VERSION ""

NS_ :

BS_:
BU_: VCU VDM SME BATT STEERING_WHEEL TPERIPH_FL TPERIPH_FR TPERIPH_BL TPERIPH_BR IZZE1 CHARGER_BOARD SMPC

BA_DEF_ "BusType" STRING ;
BA_DEF_DEF_ "BusType" "";
BA_ "BusType" "CAN";

BO_ 128 SYNC: 0 VCU

BO_ 385 SMPC_UNKNOWN_1: 0 SMPC

BO_ 641 SMPC_UNKNOWN_2: 0 SMPC

BO_ 898 SMPC_UNKNOWN_3: 0 SMPC

BO_ 1793 SMPC_UNKNOWN_4: 0 SMPC

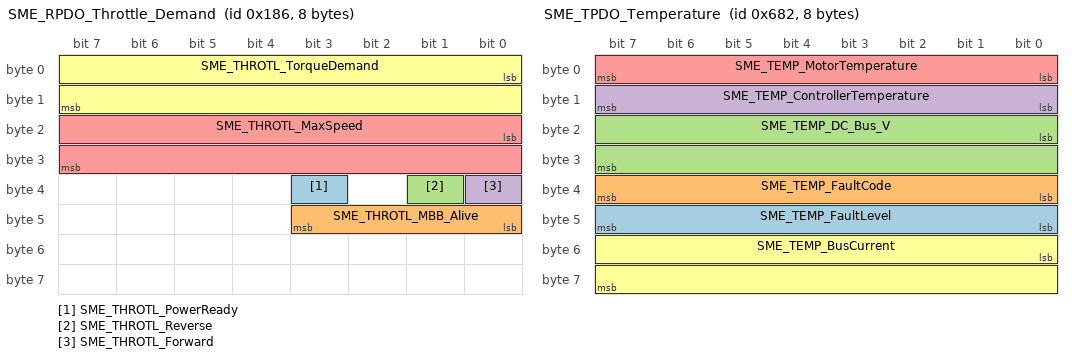
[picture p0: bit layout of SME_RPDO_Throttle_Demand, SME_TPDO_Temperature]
BO_ 390 SME_RPDO_Throttle_Demand: 8 VCU
   SG_ SME_THROTL_PowerReady : 35|1@1+ (1,0) [0|1] "" Vector__XXX
   SG_ SME_THROTL_MBB_Alive : 40|4@1+ (1,0) [0|15] "" Vector__XXX
   SG_ SME_THROTL_Reverse : 33|1@1+ (1,0) [0|1] "" Vector__XXX
   SG_ SME_THROTL_Forward : 32|1@1+ (1,0) [0|1] "" Vector__XXX
   SG_ SME_THROTL_MaxSpeed : 16|16@1- (1,0) [-32768|32767] "RPM" Vector__XXX
   SG_ SME_THROTL_TorqueDemand : 0|16@1- (1,0) [-32767|32767] "Q15" Vector__XXX

BO_ 646 SME_RPDO_Max_Currents: 8 VCU
   SG_ SME_CURRLIM_ChargeCurrentLim : 0|16@1+ (1,0) [0|65535] "A" Vector__XXX
   SG_ SME_CURRLIM_DischargeCurrentLim : 16|16@1+ (1,0) [0|65535] "A" Vector__XXX

BO_ 1154 SME_TPDO_Torque_speed: 8 SME
   SG_ SME_TRQSPD_SOC_Low_Traction : 32|1@1+ (1,0) [0|1] "" Vector__XXX
   SG_ SME_TRQSPD_SOC_Low_Hydraulic : 33|1@1+ (1,0) [0|1] "" Vector__XXX
   SG_ SME_TRQSPD_Reverse : 34|1@1+ (1,0) [0|1] "" Vector__XXX
   SG_ SME_TRQSPD_Forward : 35|1@1+ (1,0) [0|1] "" Vector__XXX
   SG_ SME_TRQSPD_Park_Brake : 36|1@1+ (1,0) [0|1] "" Vector__XXX
   SG_ SME_TRQSPD_Pedal_Brake : 37|1@1+ (1,0) [0|1] "" Vector__XXX
   SG_ SME_TRQSPD_Controller_Overtermp : 38|1@1+ (1,0) [0|1] "" Vector__XXX
   SG_ SME_TRQSPD_Key_Switch_Overvolt : 39|1@1+ (1,0) [0|1] "" Vector__XXX
   SG_ SME_TRQSPD_Key_Switch_Undervolt : 40|1@1+ (1,0) [0|1] "" Vector__XXX
   SG_ SME_TRQSPD_Running : 41|1@1+ (1,0) [0|1] "" Vector__XXX
   SG_ SME_TRQSPD_Traction : 42|1@1+ (1,0) [0|1] "" Vector__XXX
   SG_ SME_TRQSPD_Hydraulic : 43|1@1+ (1,0) [0|1] "" Vector__XXX
   SG_ SME_TRQSPD_Powering_Enabled : 44|1@1+ (1,0) [0|1] "" Vector__XXX
   SG_ SME_TRQSPD_Powering_Ready : 45|1@1+ (1,0) [0|1] "" Vector__XXX
   SG_ SME_TRQSPD_contactor_closed : 47|1@1+ (1,0) [0|1] "" Vector__XXX
   SG_ SME_TRQSPD_Precharging : 46|1@1+ (1,0) [0|1] "" Vector__XXX
   SG_ SME_TRQSPD_Speed : 0|16@1+ (1,0) [0|65535] "RPM" Vector__XXX
   SG_ SME_TRQSPD_MotorFlags : 48|16@1+ (1,0) [0|65535] "" Vector__XXX
   SG_ SME_TRQSPD_Torque : 16|16@1- (1,0) [-32767|32767] "Q15" Vector__XXX

BO_ 1666 SME_TPDO_Temperature: 8 SME
   SG_ SME_TEMP_FaultLevel : 40|8@1+ (1,0) [0|255] "" Vector__XXX
   SG_ SME_TEMP_FaultCode : 32|8@1+ (1,0) [0|255] "" Vector__XXX
   SG_ SME_TEMP_DC_Bus_V : 16|16@1+ (0.1,0) [0|6553.5] "V" Vector__XXX
   SG_ SME_TEMP_ControllerTemperature : 8|8@1+ (1,-40) [0|255] "C" Vector__XXX
   SG_ SME_TEMP_MotorTemperature : 0|8@1+ (1,-40) [0|255] "C" Vector__XXX
   SG_ SME_TEMP_BusCurrent : 48|16@1- (0.1,0) [-3276.8|3276.7] "A" Vector__XXX

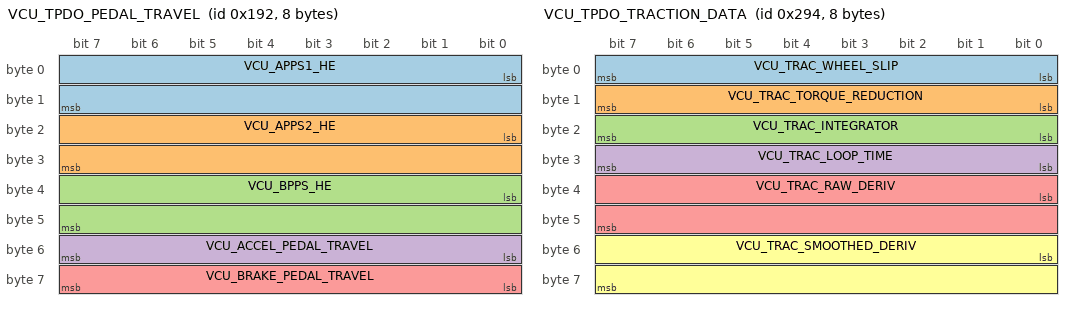
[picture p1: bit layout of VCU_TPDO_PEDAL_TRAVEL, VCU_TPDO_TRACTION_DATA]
BO_ 402 VCU_TPDO_PEDAL_TRAVEL: 8 VCU
   SG_ VCU_APPS1_HE : 0|16@1+ (1,0) [0|65535] "mV" Vector__XXX
   SG_ VCU_APPS2_HE : 16|16@1+ (1,0) [0|65535] "mV" Vector__XXX
   SG_ VCU_BPPS_HE : 32|16@1+ (1,0) [0|65535] "mV" Vector__XXX
   SG_ VCU_ACCEL_PEDAL_TRAVEL : 48|8@1+ (1,0) [0|100] "%" Vector__XXX
   SG_ VCU_BRAKE_PEDAL_TRAVEL : 56|8@1+ (1,0) [0|100] "%" Vector__XXX

BO_ 403 VCU_TPDO_STATUS: 8 VCU
   SG_ VCU_ETC_READY_TO_DRIVE : 0|1@1+ (1,0) [0|1] "" Vector__XXX
   SG_ VCU_ETC_MOTOR_ENABLED : 1|1@1+ (1,0) [0|1] "" Vector__XXX
   SG_ VCU_ETC_RTD_BUTTON_PRESSED : 2|1@1+ (1,0) [0|1] "" Vector__XXX
   SG_ VCU_ETC_BATT_PRECHARGE_DONE : 3|1@1+ (1,0) [0|1] "" Vector__XXX
   SG_ VCU_ETC_IMPLAUS_APPS_OUT_OF_RANGE : 4|1@1+ (1,0) [0|1] "" Vector__XXX
   SG_ VCU_ETC_IMPLAUS_BPPS_OUT_OF_RANGE : 5|1@1+ (1,0) [0|1] "" Vector__XXX
   SG_ VCU_ETC_IMPLAUS_APPS_DEVIATION : 6|1@1+ (1,0) [0|1] "" Vector__XXX
   SG_ VCU_ETC_IMPLAUS_BSE_OUT_OF_RANGE : 7|1@1+ (1,0) [0|1] "" Vector__XXX
   SG_ VCU_ETC_IMPLAUS_BRAKE_AND_ACCEL : 8|1@1+ (1,0) [0|1] "" Vector__XXX
   SG_ VCU_ETC_REVERSE : 9|1@1+ (1,0) [0|1] "" Vector__XXX
   SG_ VCU_ETC_BRAKELIGHT : 10|1@1+ (1,0) [0|1] "" Vector__XXX
   SG_ VCU_ETC_REGEN_ALLOWED : 11|1@1+ (1,0) [0|1] "" Vector__XXX
   SG_ VCU_ETC_SOLENOID_CLOSED : 12|1@1+ (1,0) [0|1] "" Vector__XXX
   SG_ VCU_BSPD_FAULT : 14|1@1+ (1,0) [0|1] "" Vector__XXX
   SG_ VCU_BSPD_SHUTDOWN_OUT : 15|1@1+ (1,0) [0|1] "" Vector__XXX
   SG_ VCU_BRAKE_PRESSSURE_FRONT : 16|16@1+ (1,0) [0|65535] "psi" Vector__XXX
   SG_ VCU_BRAKE_PRESSSURE_REAR : 32|16@1+ (1,0) [0|65535] "psi" Vector__XXX
   SG_ VCU_STEERING_ANGLE : 48|16@1- (0.01,0) [-327.68|327.67] "deg" Vector__XXX

  BO_ 660 VCU_TPDO_TRACTION_DATA: 8 VCU
    SG_ VCU_TRAC_WHEEL_SLIP : 0|8@1+ (0.01,0) [0|1] "" Vector__XXX
    SG_ VCU_TRAC_TORQUE_REDUCTION : 8|8@1+ (0.01,0) [0|1] "" Vector__XXX
    SG_ VCU_TRAC_INTEGRATOR : 16|8@1+ (0.01,0) [0|2.55] "" Vector__XXX
    SG_ VCU_TRAC_LOOP_TIME : 24|8@1+ (1,0) [10|255] "ms" Vector__XXX
    SG_ VCU_TRAC_RAW_DERIV : 32|16@1- (0.001,0) [-32.768|32.767] "" Vector__XXX
    SG_ VCU_TRAC_SMOOTHED_DERIV : 48|16@1- (0.001,0) [-32.768|32.767] "" Vector__XXX

BO_ 913 BATT_TPDO_STATUS: 8 BATT
   SG_ BATT_STATUS_BMS_FAULT : 0|1@1+ (1,0) [0|1] "" Vector__XXX
   SG_ BATT_STATUS_IMD_FAULT : 1|1@1+ (1,0) [0|1] "" Vector__XXX
   SG_ BATT_STATUS_SHUTDOWN_FINAL : 2|1@1+ (1,0) [0|1] "" Vector__XXX
   SG_ BATT_STATUS_SHUTDOWN_IN : 3|1@1+ (1,0) [0|1] "" Vector__XXX
   SG_ BATT_STATUS_SHUTDOWN_OUT : 4|1@1+ (1,0) [0|1] "" Vector__XXX
   SG_ BATT_STATUS_PRECHARGING : 5|1@1+ (1,0) [0|1] "" Vector__XXX
   SG_ BATT_STATUS_PRECHARGE_DONE : 6|1@1+ (1,0) [0|1] "" Vector__XXX
   SG_ BATT_STATUS_CHARGING : 7|1@1+ (1,0) [0|1] "" Vector__XXX
   SG_ BATT_STATUS_BALANCING : 8|1@1+ (1,0) [0|1] "" Vector__XXX
   SG_ BATT_STATUS_CELL_VOLTAGE_TOO_LOW : 9|1@1+ (1,0) [0|1] "" Vector__XXX
   SG_ BATT_STATUS_CELL_VOLTAGE_TOO_HIGH : 10|1@1+ (1,0) [0|1] "" Vector__XXX
   SG_ BATT_STATUS_PACK_TEMP_TOO_LOW : 11|1@1+ (1,0) [0|1] "" Vector__XXX
   SG_ BATT_STATUS_PACK_TEMP_TOO_HIGH : 12|1@1+ (1,0) [0|1] "" Vector__XXX
   SG_ BATT_STATUS_PACK_TEMP_TOO_HIGH_CRG : 13|1@1+ (1,0) [0|1] "" Vector__XXX
   SG_ BATT_STATUS_FAULT_MODULE_INDEX : 16|8@1+ (1,0) [0|4] "" Vector__XXX
   SG_ BATT_STATUS_FAULT_SENSOR_INDEX : 24|8@1+ (1,0) [0|11] "" Vector__XXX
   SG_ BATT_STATUS_FAULT_INDEX : 32|8@1+ (1,0) [0|60] "" Vector__XXX
   SG_ BATT_STATUS_GLV_VOLTAGE : 40|16@1+ (0.001,0) [0|65.635] "V" Vector__XXX
   SG_ BATT_STATUS_FAN_PWM_DUTY : 56|8@1+ (1,0) [0|100] "%" Vector__XXX

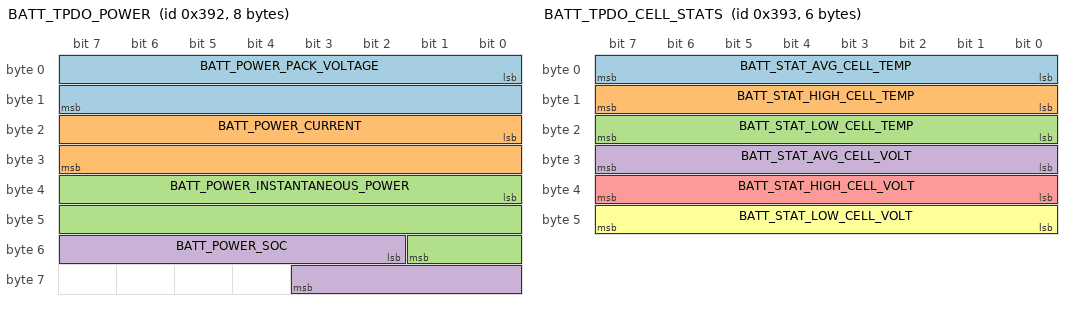
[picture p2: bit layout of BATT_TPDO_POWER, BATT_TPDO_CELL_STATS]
BO_ 914 BATT_TPDO_POWER: 8 BATT
   SG_ BATT_POWER_PACK_VOLTAGE : 0|16@1+ (0.01,0) [0|655.35] "V" Vector__XXX
   SG_ BATT_POWER_CURRENT : 16|16@1- (0.1,0) [-3276.8|3276.7] "A" Vector__XXX
   SG_ BATT_POWER_INSTANTANEOUS_POWER : 32|18@1- (1,0) [-131072|131071] "W" Vector__XXX
   SG_ BATT_POWER_SOC : 50|10@1+ (0.1,0) [0|100] "%" Vector__XXX

BO_ 915 BATT_TPDO_CELL_STATS: 6 BATT
   SG_ BATT_STAT_AVG_CELL_TEMP : 0|8@1+ (0.25,0) [0|64.0] "C" Vector__XXX
   SG_ BATT_STAT_HIGH_CELL_TEMP : 8|8@1+ (0.25,0) [0|64.0] "C" Vector__XXX
   SG_ BATT_STAT_LOW_CELL_TEMP : 16|8@1+ (0.25,0) [0|64.0] "C" Vector__XXX
   SG_ BATT_STAT_AVG_CELL_VOLT : 24|8@1+ (0.01,2) [2|4.55] "V" Vector__XXX
   SG_ BATT_STAT_HIGH_CELL_VOLT : 32|8@1+ (0.01,2) [2|4.55] "V" Vector__XXX
   SG_ BATT_STAT_LOW_CELL_VOLT : 40|8@1+ (0.01,2) [2|4.55] "V" Vector__XXX

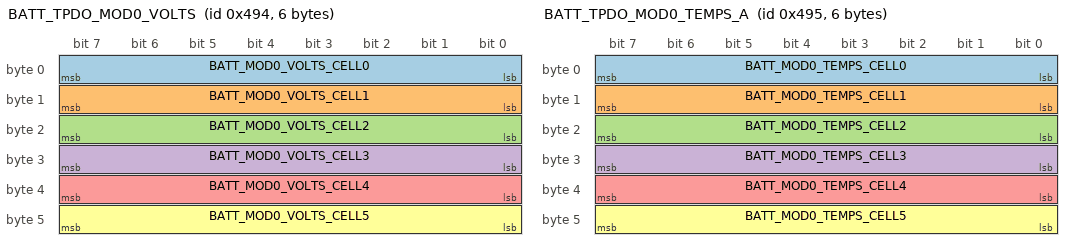
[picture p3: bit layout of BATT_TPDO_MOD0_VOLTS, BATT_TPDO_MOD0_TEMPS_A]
BO_ 1172 BATT_TPDO_MOD0_VOLTS: 6 BATT
   SG_ BATT_MOD0_VOLTS_CELL0 : 0|8@1+ (0.01,2) [2|4.55] "V" Vector__XXX
   SG_ BATT_MOD0_VOLTS_CELL1 : 8|8@1+ (0.01,2) [2|4.55] "V" Vector__XXX
   SG_ BATT_MOD0_VOLTS_CELL2 : 16|8@1+ (0.01,2) [2|4.55] "V" Vector__XXX
   SG_ BATT_MOD0_VOLTS_CELL3 : 24|8@1+ (0.01,2) [2|4.55] "V" Vector__XXX
   SG_ BATT_MOD0_VOLTS_CELL4 : 32|8@1+ (0.01,2) [2|4.55] "V" Vector__XXX
   SG_ BATT_MOD0_VOLTS_CELL5 : 40|8@1+ (0.01,2) [2|4.55] "V" Vector__XXX

BO_ 1173 BATT_TPDO_MOD0_TEMPS_A: 6 BATT
   SG_ BATT_MOD0_TEMPS_CELL0 : 0|8@1+ (0.25,0) [0|64.0] "C" Vector__XXX
   SG_ BATT_MOD0_TEMPS_CELL1 : 8|8@1+ (0.25,0) [0|64.0] "C" Vector__XXX
   SG_ BATT_MOD0_TEMPS_CELL2 : 16|8@1+ (0.25,0) [0|64.0] "C" Vector__XXX
   SG_ BATT_MOD0_TEMPS_CELL3 : 24|8@1+ (0.25,0) [0|64.0] "C" Vector__XXX
   SG_ BATT_MOD0_TEMPS_CELL4 : 32|8@1+ (0.25,0) [0|64.0] "C" Vector__XXX
   SG_ BATT_MOD0_TEMPS_CELL5 : 40|8@1+ (0.25,0) [0|64.0] "C" Vector__XXX

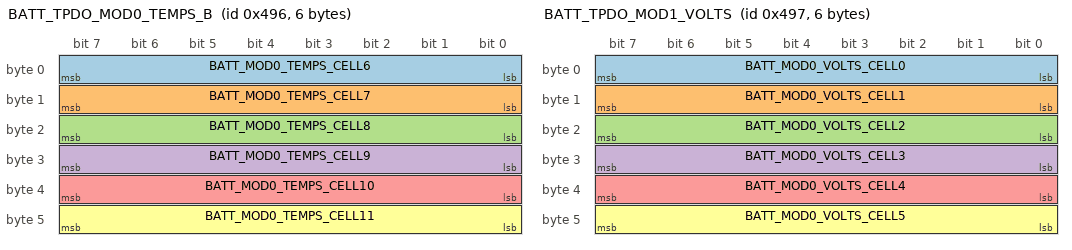
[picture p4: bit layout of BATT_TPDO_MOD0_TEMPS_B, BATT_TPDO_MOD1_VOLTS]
BO_ 1174 BATT_TPDO_MOD0_TEMPS_B: 6 BATT
   SG_ BATT_MOD0_TEMPS_CELL6 : 0|8@1+ (0.25,0) [0|64.0] "C" Vector__XXX
   SG_ BATT_MOD0_TEMPS_CELL7 : 8|8@1+ (0.25,0) [0|64.0] "C" Vector__XXX
   SG_ BATT_MOD0_TEMPS_CELL8 : 16|8@1+ (0.25,0) [0|64.0] "C" Vector__XXX
   SG_ BATT_MOD0_TEMPS_CELL9 : 24|8@1+ (0.25,0) [0|64.0] "C" Vector__XXX
   SG_ BATT_MOD0_TEMPS_CELL10 : 32|8@1+ (0.25,0) [0|64.0] "C" Vector__XXX
   SG_ BATT_MOD0_TEMPS_CELL11 : 40|8@1+ (0.25,0) [0|64.0] "C" Vector__XXX

BO_ 1175 BATT_TPDO_MOD1_VOLTS: 6 BATT
   SG_ BATT_MOD0_VOLTS_CELL0 : 0|8@1+ (0.01,2) [2|4.55] "V" Vector__XXX
   SG_ BATT_MOD0_VOLTS_CELL1 : 8|8@1+ (0.01,2) [2|4.55] "V" Vector__XXX
   SG_ BATT_MOD0_VOLTS_CELL2 : 16|8@1+ (0.01,2) [2|4.55] "V" Vector__XXX
   SG_ BATT_MOD0_VOLTS_CELL3 : 24|8@1+ (0.01,2) [2|4.55] "V" Vector__XXX
   SG_ BATT_MOD0_VOLTS_CELL4 : 32|8@1+ (0.01,2) [2|4.55] "V" Vector__XXX
   SG_ BATT_MOD0_VOLTS_CELL5 : 40|8@1+ (0.01,2) [2|4.55] "V" Vector__XXX

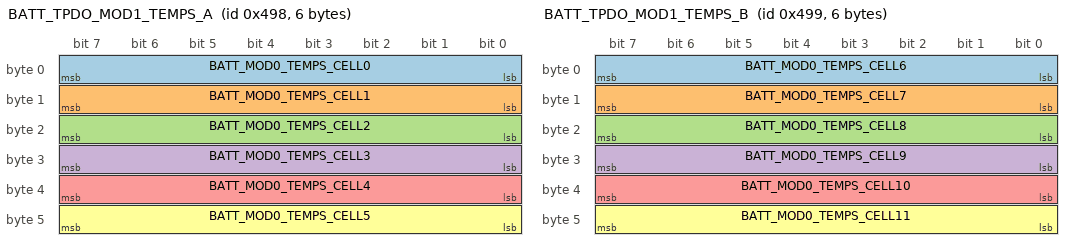
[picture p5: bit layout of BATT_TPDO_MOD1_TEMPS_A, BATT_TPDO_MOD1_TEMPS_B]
BO_ 1176 BATT_TPDO_MOD1_TEMPS_A: 6 BATT
   SG_ BATT_MOD0_TEMPS_CELL0 : 0|8@1+ (0.25,0) [0|64.0] "C" Vector__XXX
   SG_ BATT_MOD0_TEMPS_CELL1 : 8|8@1+ (0.25,0) [0|64.0] "C" Vector__XXX
   SG_ BATT_MOD0_TEMPS_CELL2 : 16|8@1+ (0.25,0) [0|64.0] "C" Vector__XXX
   SG_ BATT_MOD0_TEMPS_CELL3 : 24|8@1+ (0.25,0) [0|64.0] "C" Vector__XXX
   SG_ BATT_MOD0_TEMPS_CELL4 : 32|8@1+ (0.25,0) [0|64.0] "C" Vector__XXX
   SG_ BATT_MOD0_TEMPS_CELL5 : 40|8@1+ (0.25,0) [0|64.0] "C" Vector__XXX

BO_ 1177 BATT_TPDO_MOD1_TEMPS_B: 6 BATT
   SG_ BATT_MOD0_TEMPS_CELL6 : 0|8@1+ (0.25,0) [0|64.0] "C" Vector__XXX
   SG_ BATT_MOD0_TEMPS_CELL7 : 8|8@1+ (0.25,0) [0|64.0] "C" Vector__XXX
   SG_ BATT_MOD0_TEMPS_CELL8 : 16|8@1+ (0.25,0) [0|64.0] "C" Vector__XXX
   SG_ BATT_MOD0_TEMPS_CELL9 : 24|8@1+ (0.25,0) [0|64.0] "C" Vector__XXX
   SG_ BATT_MOD0_TEMPS_CELL10 : 32|8@1+ (0.25,0) [0|64.0] "C" Vector__XXX
   SG_ BATT_MOD0_TEMPS_CELL11 : 40|8@1+ (0.25,0) [0|64.0] "C" Vector__XXX

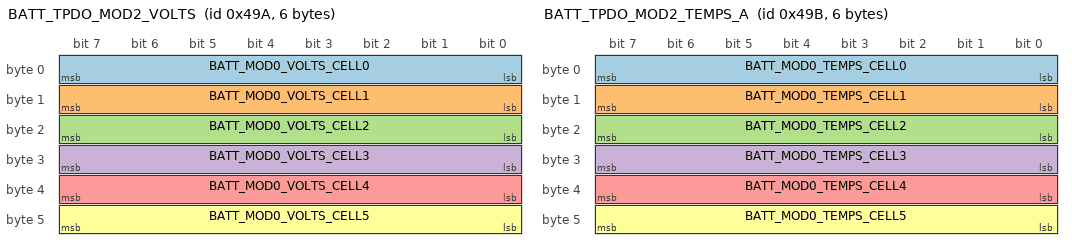
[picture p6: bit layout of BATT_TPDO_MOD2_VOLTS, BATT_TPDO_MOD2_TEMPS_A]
BO_ 1178 BATT_TPDO_MOD2_VOLTS: 6 BATT
   SG_ BATT_MOD0_VOLTS_CELL0 : 0|8@1+ (0.01,2) [2|4.55] "V" Vector__XXX
   SG_ BATT_MOD0_VOLTS_CELL1 : 8|8@1+ (0.01,2) [2|4.55] "V" Vector__XXX
   SG_ BATT_MOD0_VOLTS_CELL2 : 16|8@1+ (0.01,2) [2|4.55] "V" Vector__XXX
   SG_ BATT_MOD0_VOLTS_CELL3 : 24|8@1+ (0.01,2) [2|4.55] "V" Vector__XXX
   SG_ BATT_MOD0_VOLTS_CELL4 : 32|8@1+ (0.01,2) [2|4.55] "V" Vector__XXX
   SG_ BATT_MOD0_VOLTS_CELL5 : 40|8@1+ (0.01,2) [2|4.55] "V" Vector__XXX

BO_ 1179 BATT_TPDO_MOD2_TEMPS_A: 6 BATT
   SG_ BATT_MOD0_TEMPS_CELL0 : 0|8@1+ (0.25,0) [0|64.0] "C" Vector__XXX
   SG_ BATT_MOD0_TEMPS_CELL1 : 8|8@1+ (0.25,0) [0|64.0] "C" Vector__XXX
   SG_ BATT_MOD0_TEMPS_CELL2 : 16|8@1+ (0.25,0) [0|64.0] "C" Vector__XXX
   SG_ BATT_MOD0_TEMPS_CELL3 : 24|8@1+ (0.25,0) [0|64.0] "C" Vector__XXX
   SG_ BATT_MOD0_TEMPS_CELL4 : 32|8@1+ (0.25,0) [0|64.0] "C" Vector__XXX
   SG_ BATT_MOD0_TEMPS_CELL5 : 40|8@1+ (0.25,0) [0|64.0] "C" Vector__XXX

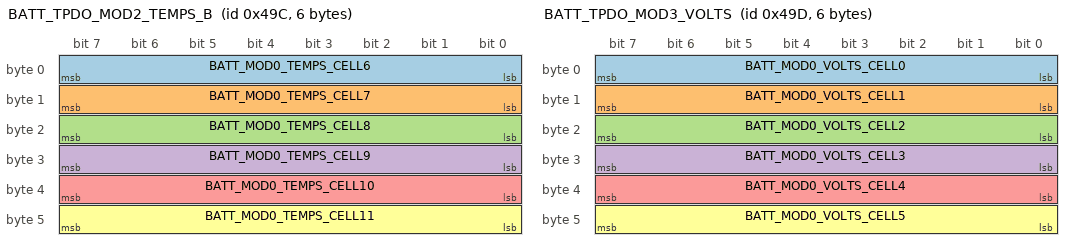
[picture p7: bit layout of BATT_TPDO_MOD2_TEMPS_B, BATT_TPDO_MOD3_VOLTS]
BO_ 1180 BATT_TPDO_MOD2_TEMPS_B: 6 BATT
   SG_ BATT_MOD0_TEMPS_CELL6 : 0|8@1+ (0.25,0) [0|64.0] "C" Vector__XXX
   SG_ BATT_MOD0_TEMPS_CELL7 : 8|8@1+ (0.25,0) [0|64.0] "C" Vector__XXX
   SG_ BATT_MOD0_TEMPS_CELL8 : 16|8@1+ (0.25,0) [0|64.0] "C" Vector__XXX
   SG_ BATT_MOD0_TEMPS_CELL9 : 24|8@1+ (0.25,0) [0|64.0] "C" Vector__XXX
   SG_ BATT_MOD0_TEMPS_CELL10 : 32|8@1+ (0.25,0) [0|64.0] "C" Vector__XXX
   SG_ BATT_MOD0_TEMPS_CELL11 : 40|8@1+ (0.25,0) [0|64.0] "C" Vector__XXX

BO_ 1181 BATT_TPDO_MOD3_VOLTS: 6 BATT
   SG_ BATT_MOD0_VOLTS_CELL0 : 0|8@1+ (0.01,2) [2|4.55] "V" Vector__XXX
   SG_ BATT_MOD0_VOLTS_CELL1 : 8|8@1+ (0.01,2) [2|4.55] "V" Vector__XXX
   SG_ BATT_MOD0_VOLTS_CELL2 : 16|8@1+ (0.01,2) [2|4.55] "V" Vector__XXX
   SG_ BATT_MOD0_VOLTS_CELL3 : 24|8@1+ (0.01,2) [2|4.55] "V" Vector__XXX
   SG_ BATT_MOD0_VOLTS_CELL4 : 32|8@1+ (0.01,2) [2|4.55] "V" Vector__XXX
   SG_ BATT_MOD0_VOLTS_CELL5 : 40|8@1+ (0.01,2) [2|4.55] "V" Vector__XXX

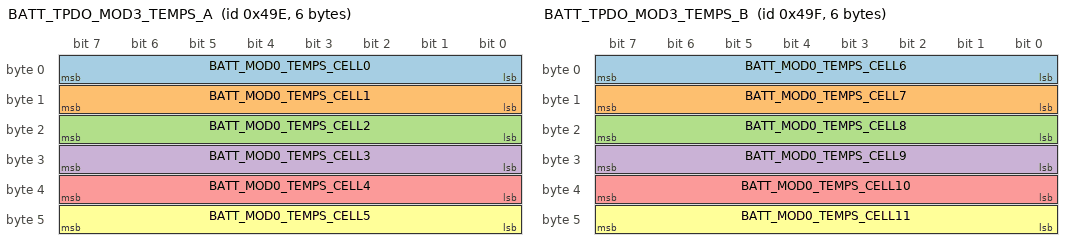
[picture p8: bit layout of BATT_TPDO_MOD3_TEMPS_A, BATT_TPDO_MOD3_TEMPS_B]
BO_ 1182 BATT_TPDO_MOD3_TEMPS_A: 6 BATT
   SG_ BATT_MOD0_TEMPS_CELL0 : 0|8@1+ (0.25,0) [0|64.0] "C" Vector__XXX
   SG_ BATT_MOD0_TEMPS_CELL1 : 8|8@1+ (0.25,0) [0|64.0] "C" Vector__XXX
   SG_ BATT_MOD0_TEMPS_CELL2 : 16|8@1+ (0.25,0) [0|64.0] "C" Vector__XXX
   SG_ BATT_MOD0_TEMPS_CELL3 : 24|8@1+ (0.25,0) [0|64.0] "C" Vector__XXX
   SG_ BATT_MOD0_TEMPS_CELL4 : 32|8@1+ (0.25,0) [0|64.0] "C" Vector__XXX
   SG_ BATT_MOD0_TEMPS_CELL5 : 40|8@1+ (0.25,0) [0|64.0] "C" Vector__XXX

BO_ 1183 BATT_TPDO_MOD3_TEMPS_B: 6 BATT
   SG_ BATT_MOD0_TEMPS_CELL6 : 0|8@1+ (0.25,0) [0|64.0] "C" Vector__XXX
   SG_ BATT_MOD0_TEMPS_CELL7 : 8|8@1+ (0.25,0) [0|64.0] "C" Vector__XXX
   SG_ BATT_MOD0_TEMPS_CELL8 : 16|8@1+ (0.25,0) [0|64.0] "C" Vector__XXX
   SG_ BATT_MOD0_TEMPS_CELL9 : 24|8@1+ (0.25,0) [0|64.0] "C" Vector__XXX
   SG_ BATT_MOD0_TEMPS_CELL10 : 32|8@1+ (0.25,0) [0|64.0] "C" Vector__XXX
   SG_ BATT_MOD0_TEMPS_CELL11 : 40|8@1+ (0.25,0) [0|64.0] "C" Vector__XXX

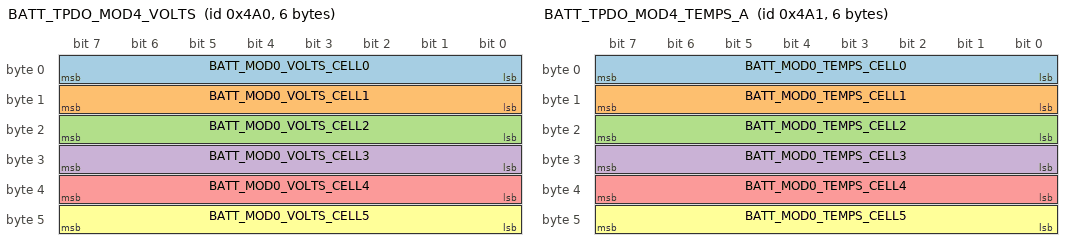
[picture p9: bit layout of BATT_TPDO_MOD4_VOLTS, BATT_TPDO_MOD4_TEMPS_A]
BO_ 1184 BATT_TPDO_MOD4_VOLTS: 6 BATT
   SG_ BATT_MOD0_VOLTS_CELL0 : 0|8@1+ (0.01,2) [2|4.55] "V" Vector__XXX
   SG_ BATT_MOD0_VOLTS_CELL1 : 8|8@1+ (0.01,2) [2|4.55] "V" Vector__XXX
   SG_ BATT_MOD0_VOLTS_CELL2 : 16|8@1+ (0.01,2) [2|4.55] "V" Vector__XXX
   SG_ BATT_MOD0_VOLTS_CELL3 : 24|8@1+ (0.01,2) [2|4.55] "V" Vector__XXX
   SG_ BATT_MOD0_VOLTS_CELL4 : 32|8@1+ (0.01,2) [2|4.55] "V" Vector__XXX
   SG_ BATT_MOD0_VOLTS_CELL5 : 40|8@1+ (0.01,2) [2|4.55] "V" Vector__XXX

BO_ 1185 BATT_TPDO_MOD4_TEMPS_A: 6 BATT
   SG_ BATT_MOD0_TEMPS_CELL0 : 0|8@1+ (0.25,0) [0|64.0] "C" Vector__XXX
   SG_ BATT_MOD0_TEMPS_CELL1 : 8|8@1+ (0.25,0) [0|64.0] "C" Vector__XXX
   SG_ BATT_MOD0_TEMPS_CELL2 : 16|8@1+ (0.25,0) [0|64.0] "C" Vector__XXX
   SG_ BATT_MOD0_TEMPS_CELL3 : 24|8@1+ (0.25,0) [0|64.0] "C" Vector__XXX
   SG_ BATT_MOD0_TEMPS_CELL4 : 32|8@1+ (0.25,0) [0|64.0] "C" Vector__XXX
   SG_ BATT_MOD0_TEMPS_CELL5 : 40|8@1+ (0.25,0) [0|64.0] "C" Vector__XXX

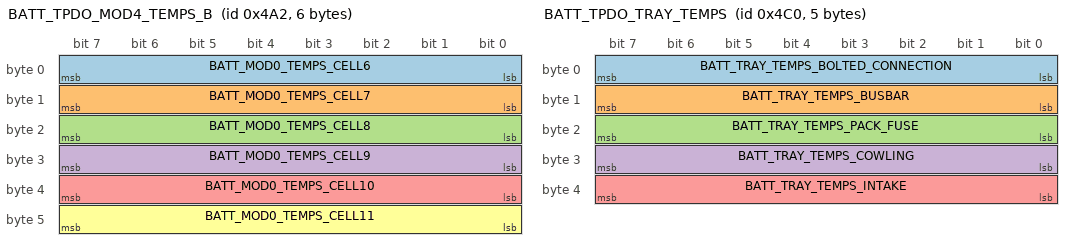
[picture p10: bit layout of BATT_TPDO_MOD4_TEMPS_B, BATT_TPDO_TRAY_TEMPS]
BO_ 1186 BATT_TPDO_MOD4_TEMPS_B: 6 BATT
   SG_ BATT_MOD0_TEMPS_CELL6 : 0|8@1+ (0.25,0) [0|64.0] "C" Vector__XXX
   SG_ BATT_MOD0_TEMPS_CELL7 : 8|8@1+ (0.25,0) [0|64.0] "C" Vector__XXX
   SG_ BATT_MOD0_TEMPS_CELL8 : 16|8@1+ (0.25,0) [0|64.0] "C" Vector__XXX
   SG_ BATT_MOD0_TEMPS_CELL9 : 24|8@1+ (0.25,0) [0|64.0] "C" Vector__XXX
   SG_ BATT_MOD0_TEMPS_CELL10 : 32|8@1+ (0.25,0) [0|64.0] "C" Vector__XXX
   SG_ BATT_MOD0_TEMPS_CELL11 : 40|8@1+ (0.25,0) [0|64.0] "C" Vector__XXX

BO_ 1216 BATT_TPDO_TRAY_TEMPS: 5 BATT
   SG_ BATT_TRAY_TEMPS_BOLTED_CONNECTION : 0|8@1+ (0.5,0) [0|127.5] "" Vector__XXX
   SG_ BATT_TRAY_TEMPS_BUSBAR : 8|8@1+ (0.5,0) [0|127.5] "" Vector__XXX
   SG_ BATT_TRAY_TEMPS_PACK_FUSE : 16|8@1+ (0.5,0) [0|127.5] "" Vector__XXX
   SG_ BATT_TRAY_TEMPS_COWLING : 24|8@1+ (0.5,0) [0|127.5] "" Vector__XXX
   SG_ BATT_TRAY_TEMPS_INTAKE : 32|8@1+ (0.5,0) [0|127.5] "" Vector__XXX

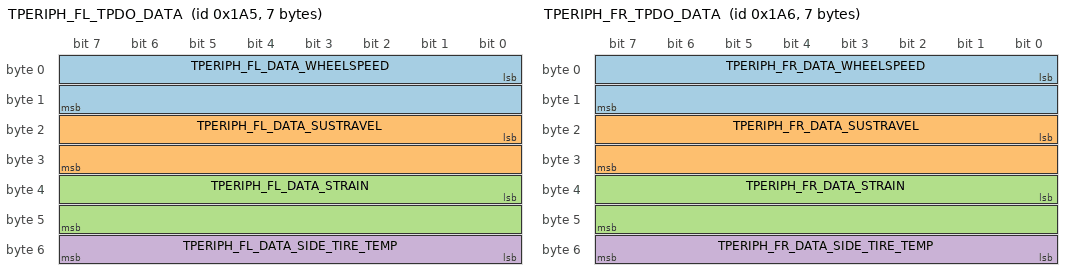
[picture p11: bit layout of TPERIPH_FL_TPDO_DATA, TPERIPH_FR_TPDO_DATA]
BO_ 421 TPERIPH_FL_TPDO_DATA: 7 TPERIPH_FL
   SG_ TPERIPH_FL_DATA_WHEELSPEED : 0|16@1- (0.1,0) [-3276.8|3276.7] "rpm" Vector__XXX
   SG_ TPERIPH_FL_DATA_SUSTRAVEL : 16|16@1+ (0.01,0) [0|655.35] "mm" Vector__XXX
   SG_ TPERIPH_FL_DATA_STRAIN : 32|16@1- (1e-07,0) [-0.032768|0.032767] "%" Vector__XXX
   SG_ TPERIPH_FL_DATA_SIDE_TIRE_TEMP : 48|8@1+ (1,0) [0|255] "C" Vector__XXX

BO_ 422 TPERIPH_FR_TPDO_DATA: 7 TPERIPH_FR
   SG_ TPERIPH_FR_DATA_WHEELSPEED : 0|16@1- (0.1,0) [-3276.8|3276.7] "rpm" Vector__XXX
   SG_ TPERIPH_FR_DATA_SUSTRAVEL : 16|16@1+ (0.01,0) [0|655.35] "mm" Vector__XXX
   SG_ TPERIPH_FR_DATA_STRAIN : 32|16@1- (1e-07,0) [-0.032768|0.032767] "%" Vector__XXX
   SG_ TPERIPH_FR_DATA_SIDE_TIRE_TEMP : 48|8@1+ (1,0) [0|255] "C" Vector__XXX

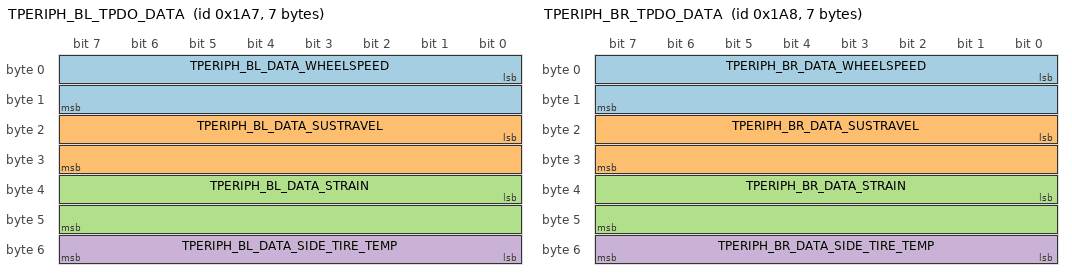
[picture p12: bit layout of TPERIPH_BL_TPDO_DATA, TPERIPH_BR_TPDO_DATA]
BO_ 423 TPERIPH_BL_TPDO_DATA: 7 TPERIPH_BL
   SG_ TPERIPH_BL_DATA_WHEELSPEED : 0|16@1- (0.1,0) [-3276.8|3276.7] "rpm" Vector__XXX
   SG_ TPERIPH_BL_DATA_SUSTRAVEL : 16|16@1+ (0.01,0) [0|655.35] "mm" Vector__XXX
   SG_ TPERIPH_BL_DATA_STRAIN : 32|16@1- (1e-07,0) [-0.032768|0.032767] "%" Vector__XXX
   SG_ TPERIPH_BL_DATA_SIDE_TIRE_TEMP : 48|8@1+ (1,0) [0|255] "C" Vector__XXX

BO_ 424 TPERIPH_BR_TPDO_DATA: 7 TPERIPH_BR
   SG_ TPERIPH_BR_DATA_WHEELSPEED : 0|16@1- (0.1,0) [-3276.8|3276.7] "rpm" Vector__XXX
   SG_ TPERIPH_BR_DATA_SUSTRAVEL : 16|16@1+ (0.01,0) [0|655.35] "mm" Vector__XXX
   SG_ TPERIPH_BR_DATA_STRAIN : 32|16@1- (1e-07,0) [-0.032768|0.032767] "%" Vector__XXX
   SG_ TPERIPH_BR_DATA_SIDE_TIRE_TEMP : 48|8@1+ (1,0) [0|255] "C" Vector__XXX

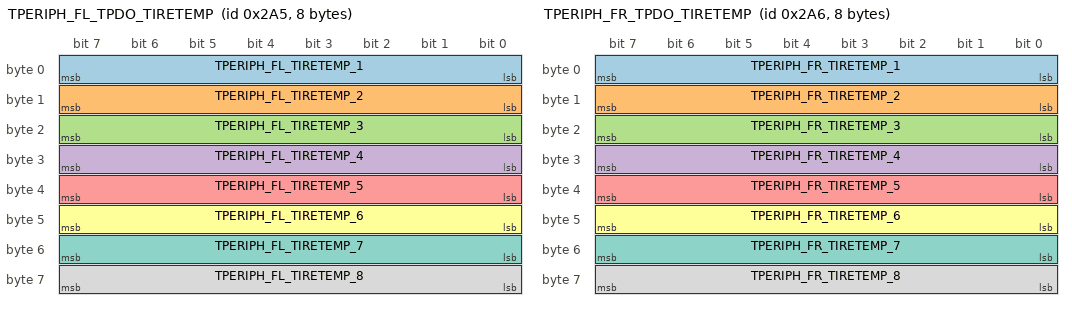
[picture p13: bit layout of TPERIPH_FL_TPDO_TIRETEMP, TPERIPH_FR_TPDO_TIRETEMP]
BO_ 677 TPERIPH_FL_TPDO_TIRETEMP: 8 TPERIPH_FL
   SG_ TPERIPH_FL_TIRETEMP_1 : 0|8@1+ (1,0) [0|255] "C" Vector__XXX
   SG_ TPERIPH_FL_TIRETEMP_2 : 8|8@1+ (1,0) [0|255] "C" Vector__XXX
   SG_ TPERIPH_FL_TIRETEMP_3 : 16|8@1+ (1,0) [0|255] "C" Vector__XXX
   SG_ TPERIPH_FL_TIRETEMP_4 : 24|8@1+ (1,0) [0|255] "C" Vector__XXX
   SG_ TPERIPH_FL_TIRETEMP_5 : 32|8@1+ (1,0) [0|255] "C" Vector__XXX
   SG_ TPERIPH_FL_TIRETEMP_6 : 40|8@1+ (1,0) [0|255] "C" Vector__XXX
   SG_ TPERIPH_FL_TIRETEMP_7 : 48|8@1+ (1,0) [0|255] "C" Vector__XXX
   SG_ TPERIPH_FL_TIRETEMP_8 : 56|8@1+ (1,0) [0|255] "C" Vector__XXX

BO_ 678 TPERIPH_FR_TPDO_TIRETEMP: 8 TPERIPH_FR
   SG_ TPERIPH_FR_TIRETEMP_1 : 0|8@1+ (1,0) [0|255] "C" Vector__XXX
   SG_ TPERIPH_FR_TIRETEMP_2 : 8|8@1+ (1,0) [0|255] "C" Vector__XXX
   SG_ TPERIPH_FR_TIRETEMP_3 : 16|8@1+ (1,0) [0|255] "C" Vector__XXX
   SG_ TPERIPH_FR_TIRETEMP_4 : 24|8@1+ (1,0) [0|255] "C" Vector__XXX
   SG_ TPERIPH_FR_TIRETEMP_5 : 32|8@1+ (1,0) [0|255] "C" Vector__XXX
   SG_ TPERIPH_FR_TIRETEMP_6 : 40|8@1+ (1,0) [0|255] "C" Vector__XXX
   SG_ TPERIPH_FR_TIRETEMP_7 : 48|8@1+ (1,0) [0|255] "C" Vector__XXX
   SG_ TPERIPH_FR_TIRETEMP_8 : 56|8@1+ (1,0) [0|255] "C" Vector__XXX

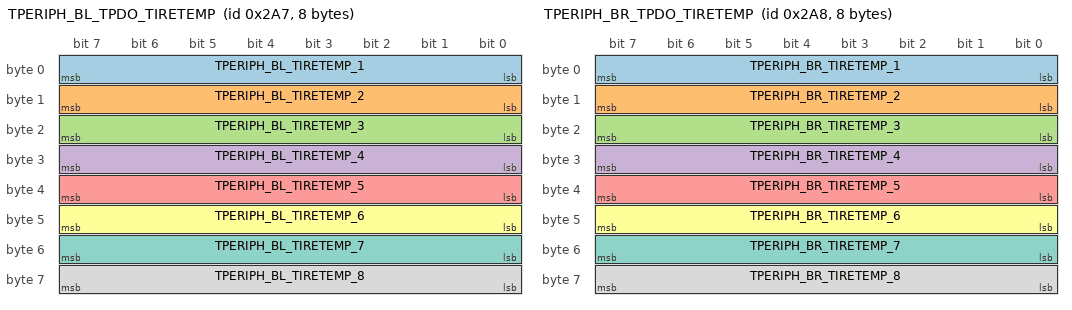
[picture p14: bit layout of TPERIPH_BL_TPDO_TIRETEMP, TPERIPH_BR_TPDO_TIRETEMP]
BO_ 679 TPERIPH_BL_TPDO_TIRETEMP: 8 TPERIPH_BL
   SG_ TPERIPH_BL_TIRETEMP_1 : 0|8@1+ (1,0) [0|255] "C" Vector__XXX
   SG_ TPERIPH_BL_TIRETEMP_2 : 8|8@1+ (1,0) [0|255] "C" Vector__XXX
   SG_ TPERIPH_BL_TIRETEMP_3 : 16|8@1+ (1,0) [0|255] "C" Vector__XXX
   SG_ TPERIPH_BL_TIRETEMP_4 : 24|8@1+ (1,0) [0|255] "C" Vector__XXX
   SG_ TPERIPH_BL_TIRETEMP_5 : 32|8@1+ (1,0) [0|255] "C" Vector__XXX
   SG_ TPERIPH_BL_TIRETEMP_6 : 40|8@1+ (1,0) [0|255] "C" Vector__XXX
   SG_ TPERIPH_BL_TIRETEMP_7 : 48|8@1+ (1,0) [0|255] "C" Vector__XXX
   SG_ TPERIPH_BL_TIRETEMP_8 : 56|8@1+ (1,0) [0|255] "C" Vector__XXX

BO_ 680 TPERIPH_BR_TPDO_TIRETEMP: 8 TPERIPH_BR
   SG_ TPERIPH_BR_TIRETEMP_1 : 0|8@1+ (1,0) [0|255] "C" Vector__XXX
   SG_ TPERIPH_BR_TIRETEMP_2 : 8|8@1+ (1,0) [0|255] "C" Vector__XXX
   SG_ TPERIPH_BR_TIRETEMP_3 : 16|8@1+ (1,0) [0|255] "C" Vector__XXX
   SG_ TPERIPH_BR_TIRETEMP_4 : 24|8@1+ (1,0) [0|255] "C" Vector__XXX
   SG_ TPERIPH_BR_TIRETEMP_5 : 32|8@1+ (1,0) [0|255] "C" Vector__XXX
   SG_ TPERIPH_BR_TIRETEMP_6 : 40|8@1+ (1,0) [0|255] "C" Vector__XXX
   SG_ TPERIPH_BR_TIRETEMP_7 : 48|8@1+ (1,0) [0|255] "C" Vector__XXX
   SG_ TPERIPH_BR_TIRETEMP_8 : 56|8@1+ (1,0) [0|255] "C" Vector__XXX

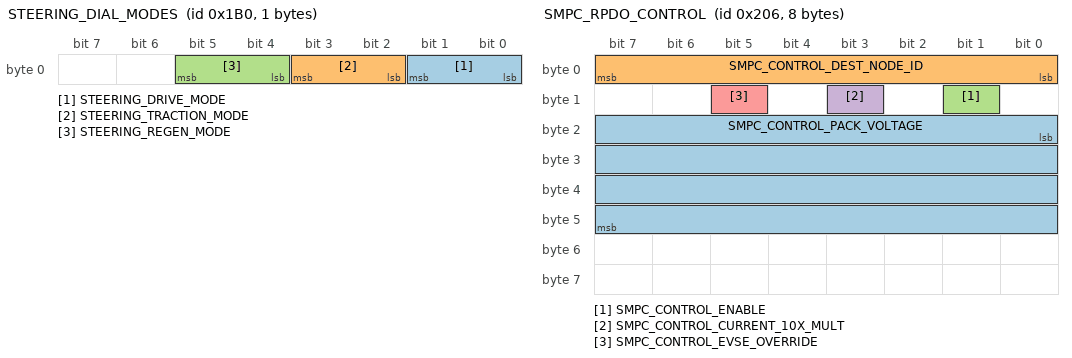
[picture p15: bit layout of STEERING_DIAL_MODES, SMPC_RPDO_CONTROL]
BO_ 432 STEERING_DIAL_MODES: 1 STEERING_WHEEL
   SG_ STEERING_DRIVE_MODE : 0|2@1+ (1,0) [0|2] "" Vector__XXX
   SG_ STEERING_TRACTION_MODE : 2|2@1+ (1,0) [0|2] "" Vector__XXX
   SG_ STEERING_REGEN_MODE : 4|2@1+ (1,0) [0|2] "" Vector__XXX

BO_ 2021 LSS_COMMAND: 8 CHARGER_BOARD
   SG_ COMMAND_MODE : 8|8@1+ (1,0) [0|0] "" Vector__XXX
   SG_ COMMAND_COMMAND_SPECIFIER : 0|8@1+ (1,0) [0|0] "" Vector__XXX

BO_ 2020 LSS_RESPONSE: 8 SMPC
   SG_ RESPONSE_COMMAND_SPECIFIER : 0|8@1+ (1,0) [0|0] "" Vector__XXX

BO_ 518 SMPC_RPDO_CONTROL: 8 CHARGER_BOARD
   SG_ SMPC_CONTROL_PACK_VOLTAGE : 16|32@1+ (1,0) [0|65535] "mV" Vector__XXX
   SG_ SMPC_CONTROL_DEST_NODE_ID : 0|8@1+ (1,0) [0|0] "" Vector__XXX
   SG_ SMPC_CONTROL_ENABLE : 9|1@1+ (1,0) [0|0] "" Vector__XXX
   SG_ SMPC_CONTROL_CURRENT_10X_MULT : 11|1@1+ (1,0) [0|0] "" Vector__XXX
   SG_ SMPC_CONTROL_EVSE_OVERRIDE : 13|1@1+ (1,0) [0|0] "" Vector__XXX

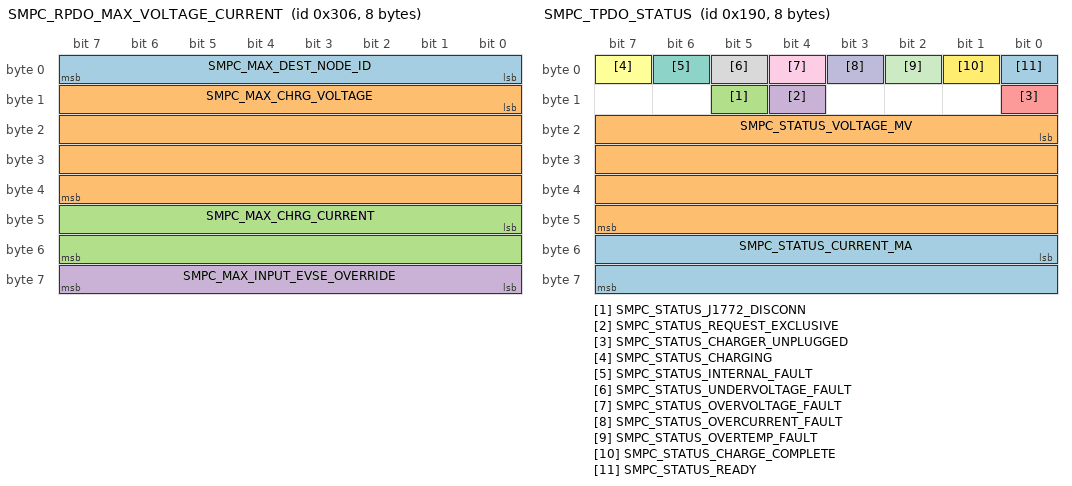
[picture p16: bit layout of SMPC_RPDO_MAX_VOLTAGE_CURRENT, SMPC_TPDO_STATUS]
BO_ 774 SMPC_RPDO_MAX_VOLTAGE_CURRENT: 8 CHARGER_BOARD
   SG_ SMPC_MAX_DEST_NODE_ID : 0|8@1+ (1,0) [0|0] "" Vector__XXX
   SG_ SMPC_MAX_CHRG_VOLTAGE : 8|32@1+ (1,0) [0|0] "mV" Vector__XXX
   SG_ SMPC_MAX_CHRG_CURRENT : 40|16@1+ (1,0) [0|0] "mA" Vector__XXX
   SG_ SMPC_MAX_INPUT_EVSE_OVERRIDE : 56|8@1+ (1,0) [0|255] "A" Vector__XXX

BO_ 400 SMPC_TPDO_STATUS: 8 SMPC
   SG_ SMPC_STATUS_CURRENT_MA : 48|16@1+ (1,0) [0|65535] "mA" Vector__XXX
   SG_ SMPC_STATUS_VOLTAGE_MV : 16|32@1+ (1,0) [0|2704] "mV" Vector__XXX
   SG_ SMPC_STATUS_J1772_DISCONN : 13|1@1+ (1,0) [0|1] "" Vector__XXX
   SG_ SMPC_STATUS_REQUEST_EXCLUSIVE : 12|1@1+ (1,0) [0|1] "" Vector__XXX
   SG_ SMPC_STATUS_CHARGER_UNPLUGGED : 8|1@1+ (1,0) [0|1] "" Vector__XXX
   SG_ SMPC_STATUS_CHARGING : 7|1@1+ (1,0) [0|1] "" Vector__XXX
   SG_ SMPC_STATUS_INTERNAL_FAULT : 6|1@1+ (1,0) [0|1] "" Vector__XXX
   SG_ SMPC_STATUS_UNDERVOLTAGE_FAULT : 5|1@1+ (1,0) [0|1] "" Vector__XXX
   SG_ SMPC_STATUS_OVERVOLTAGE_FAULT : 4|1@1+ (1,0) [0|1] "" Vector__XXX
   SG_ SMPC_STATUS_OVERCURRENT_FAULT : 3|1@1+ (1,0) [0|1] "" Vector__XXX
   SG_ SMPC_STATUS_OVERTEMP_FAULT : 2|1@1+ (1,0) [0|1] "" Vector__XXX
   SG_ SMPC_STATUS_CHARGE_COMPLETE : 1|1@1+ (1,0) [0|1] "" Vector__XXX
   SG_ SMPC_STATUS_READY : 0|1@1+ (1,0) [0|1] "" Vector__XXX

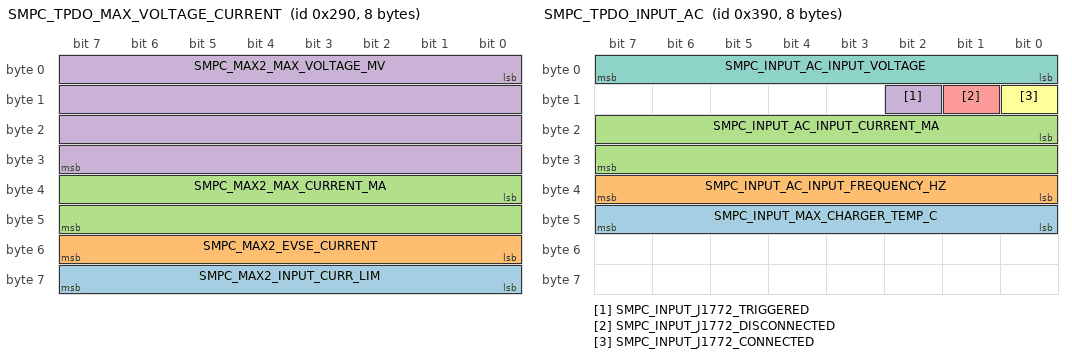
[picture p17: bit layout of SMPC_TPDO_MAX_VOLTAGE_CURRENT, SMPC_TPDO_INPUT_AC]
BO_ 656 SMPC_TPDO_MAX_VOLTAGE_CURRENT: 8 SMPC
   SG_ SMPC_MAX2_INPUT_CURR_LIM : 56|8@1+ (1,0) [0|255] "A" Vector__XXX
   SG_ SMPC_MAX2_EVSE_CURRENT : 48|8@1+ (1,0) [0|255] "A" Vector__XXX
   SG_ SMPC_MAX2_MAX_CURRENT_MA : 32|16@1+ (1,0) [0|65535] "mA" Vector__XXX
   SG_ SMPC_MAX2_MAX_VOLTAGE_MV : 0|32@1+ (1,0) [0|2704] "mV" Vector__XXX

BO_ 912 SMPC_TPDO_INPUT_AC: 8 SMPC
   SG_ SMPC_INPUT_MAX_CHARGER_TEMP_C : 40|8@1+ (1,-50) [-50|205] "C" Vector__XXX
   SG_ SMPC_INPUT_AC_INPUT_FREQUENCY_HZ : 32|8@1+ (1,0) [0|255] "HZ" Vector__XXX
   SG_ SMPC_INPUT_AC_INPUT_CURRENT_MA : 16|16@1+ (1,0) [0|65535] "mA" Vector__XXX
   SG_ SMPC_INPUT_J1772_TRIGGERED : 10|1@1+ (1,0) [0|1] "" Vector__XXX
   SG_ SMPC_INPUT_J1772_DISCONNECTED : 9|1@1+ (1,0) [0|1] "" Vector__XXX
   SG_ SMPC_INPUT_J1772_CONNECTED : 8|1@1+ (1,0) [0|1] "" Vector__XXX
   SG_ SMPC_INPUT_AC_INPUT_VOLTAGE : 0|8@1+ (1,0) [0|255] "Vac" Vector__XXX

BO_ 1168 SMPC_TPDO_SERIAL_PART_NUM: 8 SMPC
   SG_ SMPC_SER_FIRMWARE_VER : 48|16@1+ (1,0) [0|65535] "" Vector__XXX
   SG_ SMPC_SER_SERIAL_NUMBER : 16|32@1+ (1,0) [0|2704] "" Vector__XXX
   SG_ SMPC_SER_PART_NUMBER : 0|16@1+ (1,0) [0|65535] "" Vector__XXX

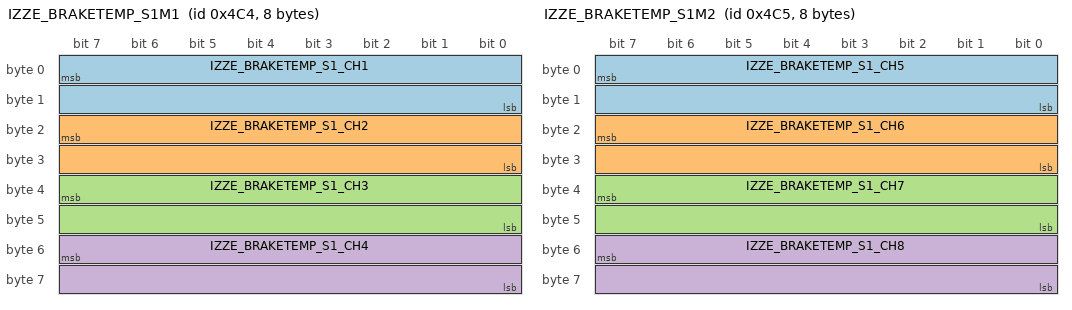
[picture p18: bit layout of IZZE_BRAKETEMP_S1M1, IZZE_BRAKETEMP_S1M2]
BO_ 1220 IZZE_BRAKETEMP_S1M1: 8 IZZE1
   SG_ IZZE_BRAKETEMP_S1_CH1 : 7|16@0+ (0.1,-100) [-100|1000] "C" Vector__XXX
   SG_ IZZE_BRAKETEMP_S1_CH2 : 23|16@0+ (0.1,-100) [-100|1000] "C" Vector__XXX
   SG_ IZZE_BRAKETEMP_S1_CH3 : 39|16@0+ (0.1,-100) [-100|1000] "C" Vector__XXX
   SG_ IZZE_BRAKETEMP_S1_CH4 : 55|16@0+ (0.1,-100) [-100|1000] "C" Vector__XXX

BO_ 1221 IZZE_BRAKETEMP_S1M2: 8 IZZE1
   SG_ IZZE_BRAKETEMP_S1_CH5 : 7|16@0+ (0.1,-100) [-100|1000] "C" Vector__XXX
   SG_ IZZE_BRAKETEMP_S1_CH6 : 23|16@0+ (0.1,-100) [-100|1000] "C" Vector__XXX
   SG_ IZZE_BRAKETEMP_S1_CH7 : 39|16@0+ (0.1,-100) [-100|1000] "C" Vector__XXX
   SG_ IZZE_BRAKETEMP_S1_CH8 : 55|16@0+ (0.1,-100) [-100|1500] "C" Vector__XXX

BO_ 1222 IZZE_BRAKETEMP_S1M3: 8 IZZE1
   SG_ IZZE_BRAKETEMP_S1_CH9 : 7|16@0+ (0.1,-100) [-100|1000] "C" Vector__XXX
   SG_ IZZE_BRAKETEMP_S1_CH10 : 23|16@0+ (0.1,-100) [-100|1000] "C" Vector__XXX
   SG_ IZZE_BRAKETEMP_S1_CH11 : 39|16@0+ (0.1,-100) [-100|1000] "C" Vector__XXX
   SG_ IZZE_BRAKETEMP_S1_CH12 : 55|16@0+ (0.1,-100) [-100|1000] "C" Vector__XXX

BO_ 1223 IZZE_BRAKETEMP_S1M4: 8 IZZE1
   SG_ IZZE_BRAKETEMP_S1_CH13 : 7|16@0+ (0.1,-100) [-100|1000] "C" Vector__XXX
   SG_ IZZE_BRAKETEMP_S1_CH14 : 23|16@0+ (0.1,-100) [-100|1000] "C" Vector__XXX
   SG_ IZZE_BRAKETEMP_S1_CH15 : 39|16@0+ (0.1,-100) [-100|1000] "C" Vector__XXX
   SG_ IZZE_BRAKETEMP_S1_CH16 : 55|16@0+ (0.1,-100) [-100|1000] "C" Vector__XXX

BO_ 1224 IZZE_BRAKETEMP_S1M5: 8 IZZE1
   SG_ IZZE_BRAKETEMP_S1_STEMP : 7|16@0+ (0.1,-100) [-100|1000] "C" Vector__XXX

BO_ 655360 VDM_GPS_LAT_LONG: 8 VDM
   SG_ VDM_GPS_Latitude : 7|32@0- (1,0) [-90|90] "deg" Vector__XXX
   SG_ VDM_GPS_Longitude : 39|32@0- (1,0) [-180|180] "deg" Vector__XXX

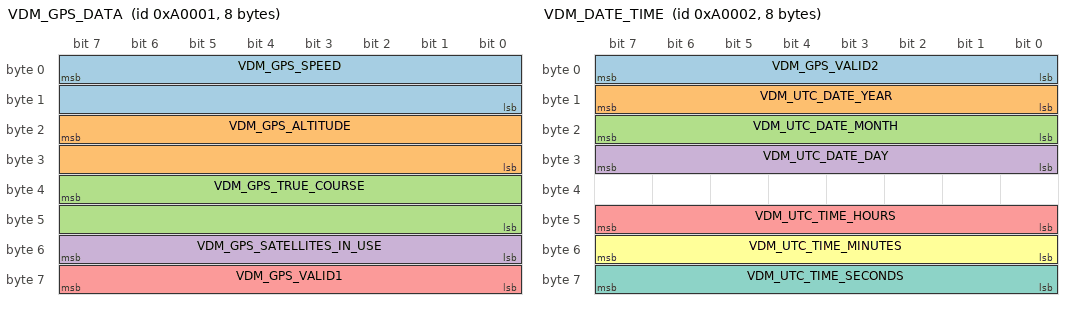
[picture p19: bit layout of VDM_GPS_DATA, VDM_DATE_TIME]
BO_ 655361 VDM_GPS_DATA: 8 VDM
   SG_ VDM_GPS_SPEED : 7|16@0+ (0.01,0) [0|655.35] "mph" Vector__XXX
   SG_ VDM_GPS_ALTITUDE : 23|16@0- (1,0) [-32768|32767] "ft" Vector__XXX
   SG_ VDM_GPS_TRUE_COURSE : 39|16@0+ (0.01,0) [0|655.35] "deg" Vector__XXX
   SG_ VDM_GPS_SATELLITES_IN_USE : 55|8@0+ (1,0) [0|255] "" Vector__XXX
   SG_ VDM_GPS_VALID1 : 63|8@0+ (1,0) [0|1] "" Vector__XXX

BO_ 655362 VDM_DATE_TIME: 8 VDM
   SG_ VDM_GPS_VALID2 : 7|8@0+ (1,0) [0|1] "" Vector__XXX
   SG_ VDM_UTC_DATE_YEAR : 15|8@0+ (1,0) [0|0] "years" Vector__XXX
   SG_ VDM_UTC_DATE_MONTH : 23|8@0+ (1,0) [0|0] "months" Vector__XXX
   SG_ VDM_UTC_DATE_DAY : 31|8@0+ (1,0) [0|0] "days" Vector__XXX
   SG_ VDM_UTC_TIME_HOURS : 47|8@0+ (1,0) [0|0] "hours" Vector__XXX
   SG_ VDM_UTC_TIME_MINUTES : 55|8@0+ (1,0) [0|0] "minutes" Vector__XXX
   SG_ VDM_UTC_TIME_SECONDS : 63|8@0+ (1,0) [0|0] "seconds" Vector__XXX

BO_ 655363 VDM_ACCELERATION: 8 VDM
   SG_ VDM_X_AXIS_ACCELERATION : 7|16@0- (0.000244141,0) [-8|8] "gs" Vector__XXX
   SG_ VDM_Y_AXIS_ACCELERATION : 23|16@0- (0.000244141,0) [-8|8] "gs" Vector__XXX
   SG_ VDM_Z_AXIS_ACCELERATION : 39|16@0- (0.000244141,0) [-8|8] "gs" Vector__XXX

BO_ 655364 VDM_YAW_RATE: 8 VDM
   SG_ VDM_X_AXIS_YAW_RATE : 7|16@0- (0.0152588,0) [-500|500] "deg/s" Vector__XXX
   SG_ VDM_Y_AXIS_YAW_RATE : 23|16@0- (0.0152588,0) [-500|500] "deg/s" Vector__XXX
   SG_ VDM_Z_AXIS_YAW_RATE : 39|16@0- (0.0152588,0) [-500|500] "deg/s" Vector__XXX

BO_ 720 VCU_IMU_ACCEL: 6 VCU
   SG_ VCU_IMU_ACCEL_ax : 0|16@1- (0.01,0) [-327.68|327.67] "m/s^2" Vector__XXX
   SG_ VCU_IMU_ACCEL_ay : 16|16@1- (0.01,0) [-327.68|327.67] "m/s^2" Vector__XXX
   SG_ VCU_IMU_ACCEL_az : 32|16@1- (0.01,0) [-327.68|327.67] "m/s^2" Vector__XXX

BO_ 976 VCU_IMU_YPR: 6 VCU
   SG_ VCU_IMU_YPR_yaw : 0|16@1- (0.01,0) [-327.68|327.67] "deg" Vector__XXX
   SG_ VCU_IMU_YPR_pitch : 16|16@1- (0.01,0) [-327.68|327.67] "deg" Vector__XXX
   SG_ VCU_IMU_YPR_roll : 32|16@1- (0.01,0) [-327.68|327.67] "deg" Vector__XXX

BO_ 721 VCU_IMU_POS_LATLON: 8 VCU
   SG_ VCU_IMU_POS_LATLON_lat : 0|32@1- (1e-07,0) [-214.748|214.748] "" Vector__XXX
   SG_ VCU_IMU_POS_LATLON_lon : 32|32@1- (1e-07,0) [-214.748|214.748] "" Vector__XXX

BO_ 977 VCU_IMU_GYRO: 6 VCU
   SG_ VCU_IMU_GYRO_wx : 0|16@1- (0.1,0) [-3276.8|3276.7] "deg/s" Vector__XXX
   SG_ VCU_IMU_GYRO_wy : 16|16@1- (0.1,0) [-3276.8|3276.7] "deg/s" Vector__XXX
   SG_ VCU_IMU_GYRO_wz : 32|16@1- (0.1,0) [-3276.8|3276.7] "deg/s" Vector__XXX

BO_ 722 VCU_IMU_VEL_BODY: 6 VCU
   SG_ VCU_IMU_VEL_BODY_vx : 0|16@1- (0.01,0) [-327.68|327.67] "m/s" Vector__XXX
   SG_ VCU_IMU_VEL_BODY_vy : 16|16@1- (0.01,0) [-327.68|327.67] "m/s" Vector__XXX
   SG_ VCU_IMU_VEL_BODY_vz : 32|16@1- (0.01,0) [-327.68|327.67] "m/s" Vector__XXX

BO_ 978 VCU_IMU_POS_ALT: 4 VCU
   SG_ VCU_IMU_POS_ALT_alt : 0|32@1- (0.001,0) [-2.14748e+06|2.14748e+06] "m" Vector__XXX

CM_ SG_ 403 VCU_ETC_IMPLAUS_APPS_OUT_OF_RANGE "APPS1 or APPS2 reading is outside of expected voltage range (for >100ms) (T.4.2.10)";
CM_ SG_ 403 VCU_ETC_IMPLAUS_BPPS_OUT_OF_RANGE "BPPS reading is outside of expected voltage range (for >100ms) (not rules-required)";
CM_ SG_ 403 VCU_ETC_IMPLAUS_APPS_DEVIATION "APPS1 and APPS2 readings deviate by >10% (for >100ms) (T.4.2.4)";
CM_ SG_ 403 VCU_ETC_IMPLAUS_BSE_OUT_OF_RANGE "Front or Rear brake pressure sensor (BSE) is outside of expected voltage range (for >100ms) (T.4.3.3/4)";
CM_ SG_ 403 VCU_ETC_IMPLAUS_BRAKE_AND_ACCEL "Mechanical braking (BSE) is engaged while APPS is at >25% pedal travel (EV.4.7)";

CM_ SG_ 403 VCU_ETC_READY_TO_DRIVE "Whether the Ready-To-Drive sequence has been completed. ETC Implausibilities will disable the motor even though RTD remains true and shutdown remains closed.";
CM_ SG_ 403 VCU_ETC_MOTOR_ENABLED "Whether the motor is enabled. True when Ready-To-Drive AND no ETC implausibilities are detected.";

CM_ SG_ 403 VCU_ETC_BATT_PRECHARGE_DONE "Whether the VCU has detected that the Tractive Battery has finished Precharging (read from BATT_TPDO_STATUS). Purely for debugging. (previously called 'TS_ACTIVE')";

CM_ SG_ 913 BATT_STATUS_SHUTDOWN_FINAL "Shutdown Circuit reading at the very end of the circuit, i.e. whether the IRs can close & Discharge can open (previously called 'IRs_Final')";
CM_ SG_ 913 BATT_STATUS_SHUTDOWN_IN "Shutdown Circuit reading after it enters the battery, before BMS & IMD relays";
CM_ SG_ 913 BATT_STATUS_SHUTDOWN_OUT "Shutdown Circuit reading before it leaves the battery, after BMS & IMD relays";

CM_ SG_ 913 BATT_STATUS_FAULT_MODULE_INDEX "The Tractive Battery module number index that the BMS fault occured in.";
CM_ SG_ 913 BATT_STATUS_FAULT_SENSOR_INDEX "The sensor index that caused the BMS fault for the given module number. For Voltage faults, this ranges from 0-5 for the 6 series cell groups in the module. For Temperature faults, this ranges from 0-11 for the 12 temperature sensors in the module.";
CM_ SG_ 913 BATT_STATUS_FAULT_INDEX "The final module-independent sensor index that caused the BMS fault. Calculated as module_index * NUM_SENSORS_PER_MODULE + sensor_index (where NUM_SENSORS_PER_MODULE is 6 for voltage faults and 12 for temperature faults).";

CM_ BO_ 2021 "Layer Setting Services (LSS) Transmit message. Sent by the charger board to the Zero SMPC charger to switch it into configuration mode";
CM_ BO_ 2020 "Layer Setting Services (LSS) Response message. Sent by the Zero SMPC charger in response to LSS configuration from the charger board";

CM_ BO_ 128 "CANopen SYNC message. Sent by the VCU.";
